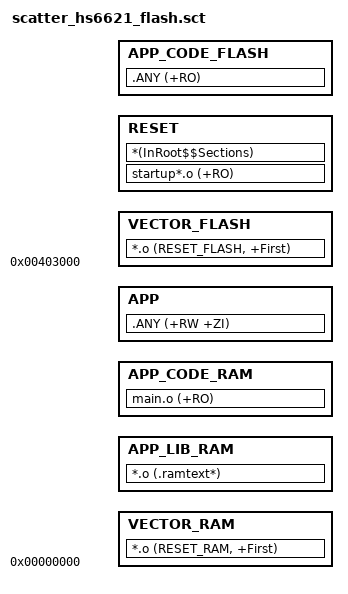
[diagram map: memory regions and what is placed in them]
#! armcc -E
; ***************************************************************
; *** Scatter-Loading Description File generated by Huntersun ***
; ***************************************************************

FLASH_LOAD 0x00403000 0x00800000
{
    ; Vector in Flash
    VECTOR_FLASH 0x00403000
    {
        *.o (RESET_FLASH, +First)
    }

    ; Startup and Keil Root code in Flash
    RESET +0
    {
        startup*.o (+RO)
        *(InRoot$$Sections)
    }

    ; Other Code in Flash
    APP_CODE_FLASH +0
    {
        .ANY (+RO)
    }

    ; Vector in RAM
    VECTOR_RAM 0
    {
        *.o (RESET_RAM, +First)
    }

    ; Critical library code in RAM
    APP_LIB_RAM +0
    {
        *.o (.ramtext*)
        ; *mc_w.l (+RO)
        ; *mf_w.l (+RO)
    }

    ; User critical code in RAM
    APP_CODE_RAM +0
    {
        main.o (+RO)
    }

    ; Data in RAM
    APP 0x20000000 + AlignExpr(ImageLimit(APP_CODE_RAM), 8)
    {
        .ANY (+RW +ZI)
    }

}

ScatterAssert(ImageLimit(RESET) < (0x00403000+0x00002000))
ScatterAssert(ImageLimit(APP)   < (0x20000000+0x0000f330))

